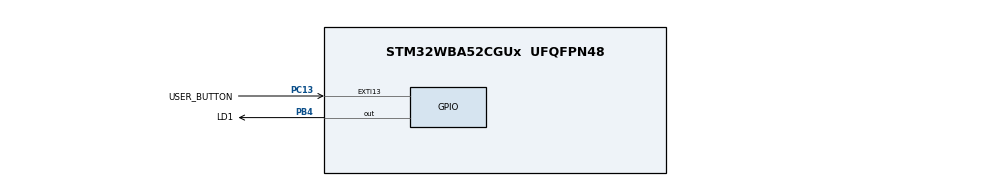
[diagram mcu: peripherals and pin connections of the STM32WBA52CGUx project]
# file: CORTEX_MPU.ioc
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CORTEX_M33_NS.userName=CORTEX_M33
Mcu.Family=STM32WBA
Mcu.Name=STM32WBA52CGUx
Mcu.Package=UFQFPN48
NVIC.EXTI13_IRQn=true\:0\:0\:false\:false\:true\:true\:true\:true
NVIC.PriorityGroup=NVIC_PRIORITYGROUP_4
OSC_IN.Mode=HSE-External-Oscillator
OSC_IN.Signal=RCC_OSC_IN
OSC_OUT.Mode=HSE-External-Oscillator
OSC_OUT.Signal=RCC_OSC_OUT
PB4\ (NJTRST).GPIO_Label=LD1
PB4\ (NJTRST).PinState=GPIO_PIN_SET
PB4\ (NJTRST).Signal=GPIO_Output
PC13.GPIO_Label=USER_BUTTON
PC13.GPIO_ModeDefaultEXTI=GPIO_MODE_IT_FALLING
PC13.GPIO_PuPd=GPIO_PULLUP
PC13.Signal=GPXTI13
ProjectManager.HeapSize=0x200
ProjectManager.StackSize=0x400
ProjectManager.TargetToolchain=EWARM V9.20
RCC.ADCFreq_Value=100000000
RCC.AHB5CLKDivider=DIV4
RCC.AHBFreq_Value=100000000
RCC.APB1Freq_Value=100000000
RCC.APB1TimFreq_Value=100000000
RCC.APB2Freq_Value=100000000
RCC.APB2TimFreq_Value=100000000
RCC.CortexFreq_Value=12500000
RCC.HCLKFreq_Value=100000000
RCC.HSE_VALUE=32000000
RCC.HSI_VALUE=16000000
RCC.LSE_VALUE=32768
RCC.PLLFRACN=0
RCC.PLLM=4
RCC.PLLN=25
RCC.PLLSourceVirtual=RCC_PLLSOURCE_HSE
RCC.SYSCLKFreq_VALUE=100000000
RCC.SYSCLKSourceVirtual=RCC_SYSCLKSOURCE_PLLCLK
RCC.VCOOutputFreq_Value=200000000
VP_ICACHE_VS_ICACHE.Mode=DirectMappedCache
VP_PWR_VS_SECSignals.Mode=Security/Privilege
board=custom

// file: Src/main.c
/* USER CODE BEGIN Header */
/**
  ******************************************************************************
  * @file    Examples_LL/CORTEX/CORTEX_MPU/Src/main.c
  * @author  MCD Application Team
  * @brief   This example presents the MPU features through
  *          the STM32WBAxx CORTEX LL API.
  ******************************************************************************
  * @attention
  *
  * Copyright (c) 2022 STMicroelectronics.
  * All rights reserved.
  *
  * This software is licensed under terms that can be found in the LICENSE file
  * in the root directory of this software component.
  * If no LICENSE file comes with this software, it is provided AS-IS.
  *
  ******************************************************************************
  */
/* USER CODE END Header */
#include "main.h"

/* USER CODE BEGIN PD */

#define ARRAY_SIZE                               (0x00000100UL)
#define ARRAY_ADDRESS_START                      (0x20002000UL)
#define ARRAY_ATTRIBUTE_NUMBER                   LL_MPU_ATTRIBUTES_NUMBER3
#define REGION_NUMBER                            LL_MPU_REGION_NUMBER3
#define EXAMPLE_RAM_ADDRESS_START                (0x20000000UL)
#define EXAMPLE_RAM_SIZE                         SRAM1_SIZE
#define EXAMPLE_PERIPH_ADDRESS_START             (0x40000000)
#define EXAMPLE_PERIPH_SIZE                      (0x1F400000UL)
#define EXAMPLE_FLASH_ADDRESS_START              (0x08000000)
#define EXAMPLE_FLASH_SIZE                       FLASH_SIZE
#define EXAMPLE_RAM_REGION_NUMBER                LL_MPU_REGION_NUMBER0
#define EXAMPLE_FLASH_REGION_NUMBER              LL_MPU_REGION_NUMBER1
#define EXAMPLE_PERIPH_REGION_NUMBER             LL_MPU_REGION_NUMBER2
#define EXAMPLE_RAM_ATTRIBUTE_NUMBER             LL_MPU_ATTRIBUTES_NUMBER0
#define EXAMPLE_FLASH_ATTRIBUTE_NUMBER           LL_MPU_ATTRIBUTES_NUMBER1
#define EXAMPLE_PERIPH_ATTRIBUTE_NUMBER          LL_MPU_ATTRIBUTES_NUMBER2
#define portMPU_REGION_READ_WRITE                LL_MPU_REGION_ALL_RW
#define portMPU_REGION_PRIVILEGED_READ_ONLY      LL_MPU_REGION_PRIV_RO
#define portMPU_REGION_READ_ONLY                 LL_MPU_REGION_PRIV_RO_URO
#define portMPU_REGION_PRIVILEGED_READ_WRITE     LL_MPU_REGION_PRIV_RW

/* USER CODE END PD */

/* USER CODE BEGIN PV */
#if defined ( __ICCARM__ )
#pragma location=ARRAY_ADDRESS_START
__no_init uint8_t PrivilegedReadOnlyArray[ARRAY_SIZE];
#elif defined   (  __GNUC__  ) || defined(__ARMCC_VERSION)
uint8_t PrivilegedReadOnlyArray[ARRAY_SIZE] __attribute__((section(".ROarraySection")));
#endif

/* USER CODE END PV */

void SystemClock_Config(void);
static void MX_GPIO_Init(void);
static void MX_ICACHE_Init(void);
/* USER CODE BEGIN PFP */

void     Configure_MPU(void);
void     MPU_AccessPermConfig(void);
void     LED_Blinking(uint32_t Period);

/* USER CODE END PFP */

int main(void)
{
  /* USER CODE BEGIN 1 */

  /* Configure the system clock to 100 MHz */

  /* USER CODE END 1 */

  /* MCU Configuration--------------------------------------------------------*/

  /* Reset of all peripherals, Initializes the Flash interface and the Systick. */

  /* System interrupt init*/
  NVIC_SetPriorityGrouping(NVIC_PRIORITYGROUP_4);

  /* Enable PWR clock interface */

  LL_AHB4_GRP1_EnableClock(LL_AHB4_GRP1_PERIPH_PWR);

  /* Configure the system clock */
  SystemClock_Config();

  /* Initialize all configured peripherals */
  MX_GPIO_Init();
  MX_ICACHE_Init();
  /* USER CODE BEGIN 2 */

  /* Set MPU regions */
  Configure_MPU();
  MPU_AccessPermConfig();

  /* Toggle quickly the LED in waiting for User-button press */
  LED_Blinking(LED_BLINK_FAST);

  /* USER CODE END 2 */

  /* Infinite loop */
  while (1)
  {

  }
}

void SystemClock_Config(void)
{
  LL_FLASH_SetLatency(LL_FLASH_LATENCY_3);
  while(LL_FLASH_GetLatency()!= LL_FLASH_LATENCY_3)
  {
  }

  LL_PWR_SetRegulVoltageScaling(LL_PWR_REGU_VOLTAGE_SCALE1);
  LL_RCC_HSE_Enable();

   /* Wait till HSE is ready */
  while(LL_RCC_HSE_IsReady() != 1)
  {
  }

  LL_RCC_PLL1_ConfigDomain_SYS(LL_RCC_PLL1SOURCE_HSE, 4, 25, 2);
  LL_RCC_PLL1_EnableDomain_PLL1R();
  LL_RCC_PLL1_SetVCOInputRange(LL_RCC_PLLINPUTRANGE_8_16);
  LL_RCC_PLL1_Enable();

   /* Wait till PLL is ready */
  while(LL_RCC_PLL1_IsReady() != 1)
  {
  }

  LL_RCC_SetSysClkSource(LL_RCC_SYS_CLKSOURCE_PLL1R);

   /* Wait till System clock is ready */
  while(LL_RCC_GetSysClkSource() != LL_RCC_SYS_CLKSOURCE_STATUS_PLL1R)
  {
  }

  LL_RCC_SetAHBPrescaler(LL_RCC_SYSCLK_DIV_1);
  LL_RCC_SetAHB5Prescaler(LL_RCC_AHB5_DIV_4);
  LL_RCC_SetAPB1Prescaler(LL_RCC_APB1_DIV_1);
  LL_RCC_SetAPB2Prescaler(LL_RCC_APB2_DIV_1);
  LL_RCC_SetAPB7Prescaler(LL_RCC_APB7_DIV_1);

  LL_Init1msTick(100000000);

  LL_SetSystemCoreClock(100000000);
}

static void MX_ICACHE_Init(void)
{

  /** Enable instruction cache in 1-way (direct mapped cache)
  */
  LL_ICACHE_SetMode(LL_ICACHE_1WAY);
  LL_ICACHE_Enable();

}

static void MX_GPIO_Init(void)
{
  LL_EXTI_InitTypeDef EXTI_InitStruct = {0};
  LL_GPIO_InitTypeDef GPIO_InitStruct = {0};

  /* GPIO Ports Clock Enable */
  LL_AHB2_GRP1_EnableClock(LL_AHB2_GRP1_PERIPH_GPIOC);
  LL_AHB2_GRP1_EnableClock(LL_AHB2_GRP1_PERIPH_GPIOB);

  /**/
  LL_GPIO_SetOutputPin(LD1_GPIO_Port, LD1_Pin);

  /**/
  LL_EXTI_SetEXTISource(LL_EXTI_CONFIG_PORTC, LL_EXTI_CONFIG_LINE13);

  /**/
  EXTI_InitStruct.Line_0_31 = LL_EXTI_LINE_13;
  EXTI_InitStruct.LineCommand = ENABLE;
  EXTI_InitStruct.Mode = LL_EXTI_MODE_IT;
  EXTI_InitStruct.Trigger = LL_EXTI_TRIGGER_FALLING;
  LL_EXTI_Init(&EXTI_InitStruct);

  /**/
  LL_GPIO_SetPinPull(USER_BUTTON_GPIO_Port, USER_BUTTON_Pin, LL_GPIO_PULL_UP);

  /**/
  LL_GPIO_SetPinMode(USER_BUTTON_GPIO_Port, USER_BUTTON_Pin, LL_GPIO_MODE_INPUT);

  /**/
  GPIO_InitStruct.Pin = LD1_Pin;
  GPIO_InitStruct.Mode = LL_GPIO_MODE_OUTPUT;
  GPIO_InitStruct.Speed = LL_GPIO_SPEED_FREQ_LOW;
  GPIO_InitStruct.OutputType = LL_GPIO_OUTPUT_PUSHPULL;
  GPIO_InitStruct.Pull = LL_GPIO_PULL_NO;
  LL_GPIO_Init(LD1_GPIO_Port, &GPIO_InitStruct);

  /* EXTI interrupt init*/
  NVIC_SetPriority(EXTI13_IRQn, NVIC_EncodePriority(NVIC_GetPriorityGrouping(),0, 0));
  NVIC_EnableIRQ(EXTI13_IRQn);

}

/* USER CODE BEGIN 4 */

/**
  * @brief  Configures the main MPU regions.
  * @param  None
  * @retval None
  */
void Configure_MPU(void)
{
  /* Disable MPU */
  LL_MPU_Disable();

  /* Configure RAM region as Region Number 0, 128KB of size and R/W region */
  /* Configure MPU attribute index */
  LL_MPU_ConfigAttributes(EXAMPLE_RAM_ATTRIBUTE_NUMBER, LL_MPU_NOT_CACHEABLE);

  /* Enable MPU region */
  LL_MPU_EnableRegion(EXAMPLE_RAM_REGION_NUMBER);

  LL_MPU_ConfigRegion(EXAMPLE_RAM_REGION_NUMBER, portMPU_REGION_READ_WRITE | LL_MPU_ACCESS_NOT_SHAREABLE |
                      LL_MPU_INSTRUCTION_ACCESS_ENABLE, EXAMPLE_RAM_ATTRIBUTE_NUMBER,EXAMPLE_RAM_ADDRESS_START,
                      (EXAMPLE_RAM_ADDRESS_START + EXAMPLE_RAM_SIZE - 1));

  /* Configure FLASH region as REGION Number 1, 1MB of size and R/W region */
  /* Configure MPU attribute index */
  LL_MPU_ConfigAttributes(EXAMPLE_FLASH_ATTRIBUTE_NUMBER, LL_MPU_NOT_CACHEABLE);

  /* Enable MPU region */
  LL_MPU_EnableRegion(EXAMPLE_FLASH_REGION_NUMBER);

  LL_MPU_ConfigRegion(EXAMPLE_FLASH_REGION_NUMBER, portMPU_REGION_READ_WRITE | LL_MPU_ACCESS_NOT_SHAREABLE |
                      LL_MPU_INSTRUCTION_ACCESS_ENABLE, EXAMPLE_FLASH_ATTRIBUTE_NUMBER, EXAMPLE_FLASH_ADDRESS_START,
                      (EXAMPLE_FLASH_ADDRESS_START + EXAMPLE_FLASH_SIZE - 1));

  /* Configure Peripheral region as REGION Number 2, 512MB of size, R/W and Execute
  Never region */
  /* Configure MPU attribute index */
  LL_MPU_ConfigAttributes(EXAMPLE_PERIPH_ATTRIBUTE_NUMBER, LL_MPU_NOT_CACHEABLE);

  /* Enable MPU region */
  LL_MPU_EnableRegion(EXAMPLE_PERIPH_REGION_NUMBER);

  LL_MPU_ConfigRegion(EXAMPLE_PERIPH_REGION_NUMBER, portMPU_REGION_READ_WRITE | LL_MPU_ACCESS_NOT_SHAREABLE |
                      LL_MPU_INSTRUCTION_ACCESS_ENABLE, EXAMPLE_PERIPH_ATTRIBUTE_NUMBER, EXAMPLE_PERIPH_ADDRESS_START,
                      (EXAMPLE_PERIPH_ADDRESS_START + EXAMPLE_PERIPH_SIZE - 1));

  /* Enable MPU (any access not covered by any enabled region will cause a fault) */
  LL_MPU_Enable(LL_MPU_CTRL_PRIVILEGED_DEFAULT);
}

/**
  * @brief  This function configures the access right using Cortex-M33 MPU regions.
  * @param  None
  * @retval None
  */
void MPU_AccessPermConfig(void)
{
  /* Configure region for PrivilegedReadOnlyArray as REGION Number 3, 32byte and R
     only in privileged mode */
  /* Disable MPU */
  LL_MPU_Disable();

  /* Configure MPU attribute index */
  LL_MPU_ConfigAttributes(ARRAY_ATTRIBUTE_NUMBER, LL_MPU_NOT_CACHEABLE);

  /* Enable MPU region */
  LL_MPU_EnableRegion(REGION_NUMBER);

  LL_MPU_ConfigRegion(REGION_NUMBER, portMPU_REGION_PRIVILEGED_READ_ONLY | LL_MPU_ACCESS_NOT_SHAREABLE |
                      LL_MPU_INSTRUCTION_ACCESS_ENABLE, ARRAY_ATTRIBUTE_NUMBER, ARRAY_ADDRESS_START,
                      (ARRAY_ADDRESS_START + ARRAY_SIZE - 1));

  /* Enable MPU (any access not covered by any enabled region will cause a fault) */
  LL_MPU_Enable(LL_MPU_CTRL_PRIVILEGED_DEFAULT);

  /* Read from PrivilegedReadOnlyArray. This will not generate error */
  (void)PrivilegedReadOnlyArray[ARRAY_SIZE - 1];
}

/**
  * @brief  Set LED to Blinking mode for an infinite loop (toggle period based on value provided as input parameter).
  * @param  Period : Period of time (in ms) between each toggling of LED
  *   This parameter can be user defined values. Pre-defined values used in that example are :
  *     @arg LED_BLINK_FAST : Fast Blinking
  *     @arg LED_BLINK_SLOW : Slow Blinking
  *     @arg LED_BLINK_ERROR : Error specific Blinking
  * @retval None
  */
void LED_Blinking(uint32_t Period)
{
  /* Toggle IO in an infinite loop */
  while (1)
  {
    LL_GPIO_TogglePin(LD1_GPIO_Port, LD1_Pin);
    LL_mDelay(Period);
  }
}

/******************************************************************************/
/*   USER IRQ HANDLER TREATMENT                                               */
/******************************************************************************/
/**
  * @brief  Function to manage User button IRQ Handler
  * @param  None
  * @retval None
  */
void UserButton_Callback(void)
{
  /* This will generate error */
  PrivilegedReadOnlyArray[ARRAY_SIZE - 1] = 'e';
}

/* USER CODE END 4 */

void Error_Handler(void)
{
}
